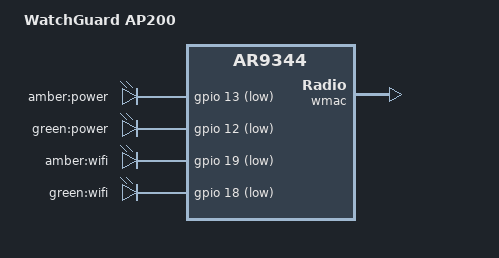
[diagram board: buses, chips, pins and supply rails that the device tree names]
// SPDX-License-Identifier: GPL-2.0-or-later OR MIT

#include "ar9344_senao_ap-dual.dtsi"

/ {
	compatible = "watchguard,ap200", "qca,ar9344";
	model = "WatchGuard AP200";

	leds {
		compatible = "gpio-leds";

		led_power: power_amber {
			label = "amber:power";
			gpios = <&gpio 13 GPIO_ACTIVE_LOW>;
			default-state = "on";
		};

		power_green {
			label = "green:power";
			gpios = <&gpio 12 GPIO_ACTIVE_LOW>;
			default-state = "on";
		};

		wifi_amber {
			label = "amber:wifi";
			gpios = <&gpio 19 GPIO_ACTIVE_LOW>;
			linux,default-trigger = "phy1tpt";
		};

		wifi_green {
			label = "green:wifi";
			gpios = <&gpio 18 GPIO_ACTIVE_LOW>;
			linux,default-trigger = "phy0tpt";
		};
	};
};

&ref {
	clock-frequency = <25000000>;
};

&eth0 {
	mtd-mac-address = <&art 0x0>;
	mtd-mac-address-increment = <(-2)>;
};

&pcie {
	wifi@0,0,0 {
		mtd-mac-address = <&art 0x0>;
		mtd-mac-address-increment = <(-1)>;
	};
};

&wmac {
	mtd-mac-address = <&art 0x0>;
	mtd-mac-address-increment = <(-2)>;
};
